VERSION "HIPBNYYYYYYYYYYYYYYYYYYYYYYYYYYYYYYYYYYYYY/4/%%%/4/'%**4YYY///"

NS_ :

BS_:

BU_: RMS_PM_Controller

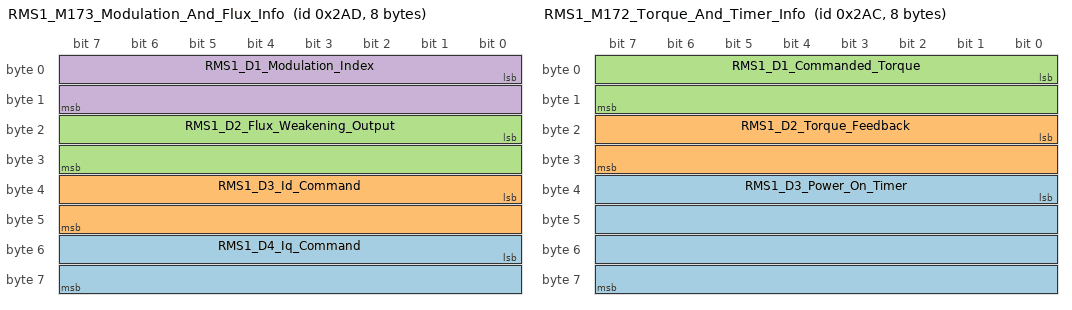
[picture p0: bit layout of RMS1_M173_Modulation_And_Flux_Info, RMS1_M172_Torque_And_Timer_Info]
BO_ 685 RMS1_M173_Modulation_And_Flux_Info: 8 RMS_PM_Controller
 SG_ RMS1_D4_Iq_Command : 48|16@1- (0.1,0) [-3276.8|3276.7] "A" Vector__XXX
 SG_ RMS1_D3_Id_Command : 32|16@1- (0.1,0) [-3276.8|3276.7] "A" Vector__XXX
 SG_ RMS1_D2_Flux_Weakening_Output : 16|16@1- (0.1,0) [-3276.8|3276.7] "A" Vector__XXX
 SG_ RMS1_D1_Modulation_Index : 0|16@1- (0.0001,0) [-3.2768|3.2767] "" Vector__XXX

BO_ 684 RMS1_M172_Torque_And_Timer_Info: 8 RMS_PM_Controller
 SG_ RMS1_D3_Power_On_Timer : 32|32@1+ (0.003,0) [0|1.28848e+007] "Sec" Vector__XXX
 SG_ RMS1_D2_Torque_Feedback : 16|16@1- (0.1,0) [-3276.8|3276.7] "Nm" Vector__XXX
 SG_ RMS1_D1_Commanded_Torque : 0|16@1- (0.1,0) [-3276.8|3276.7] "Nm" Vector__XXX

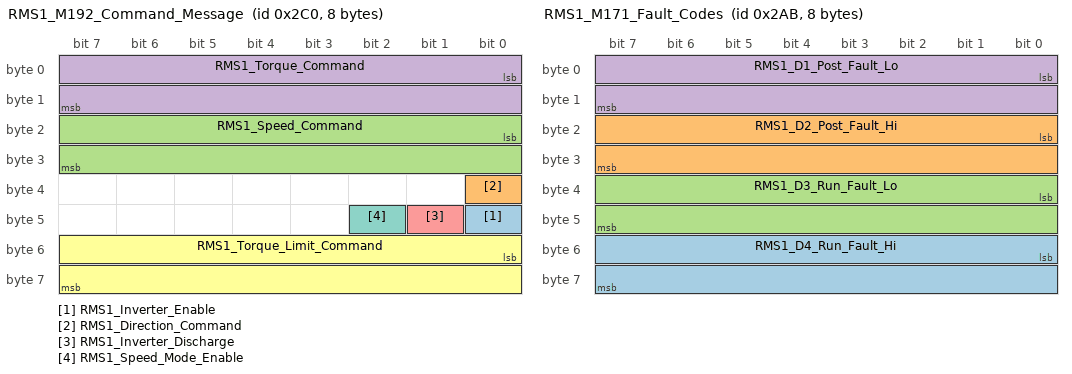
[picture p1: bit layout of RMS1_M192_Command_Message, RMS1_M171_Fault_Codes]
BO_ 704 RMS1_M192_Command_Message: 8 Vector__XXX
 SG_ RMS1_Inverter_Enable : 40|1@1+ (1,0) [0|1] "Bit" Vector__XXX
 SG_ RMS1_Direction_Command : 32|1@1+ (1,0) [0|1] "Bit" Vector__XXX
 SG_ RMS1_Speed_Command : 16|16@1- (1,0) [-32768|32767] "rpm" Vector__XXX
 SG_ RMS1_Torque_Command : 0|16@1- (0.1,0) [-3276.8|3276.7] "Nm" Vector__XXX
 SG_ RMS1_Inverter_Discharge : 41|1@1+ (1,0) [0|1] "Bit" Vector__XXX
 SG_ RMS1_Torque_Limit_Command : 48|16@1- (0.1,0) [-3276.8|3276.7] "Nm" Vector__XXX
 SG_ RMS1_Speed_Mode_Enable : 42|1@1+ (1,0) [0|1] "Bit" Vector__XXX

BO_ 683 RMS1_M171_Fault_Codes: 8 RMS_PM_Controller
 SG_ RMS1_D4_Run_Fault_Hi : 48|16@1+ (1,0) [0|65535] "" Vector__XXX
 SG_ RMS1_D2_Post_Fault_Hi : 16|16@1+ (1,0) [0|65535] "" Vector__XXX
 SG_ RMS1_D3_Run_Fault_Lo : 32|16@1+ (1,0) [0|65535] "" Vector__XXX
 SG_ RMS1_D1_Post_Fault_Lo : 0|16@1+ (1,0) [0|65535] "" Vector__XXX

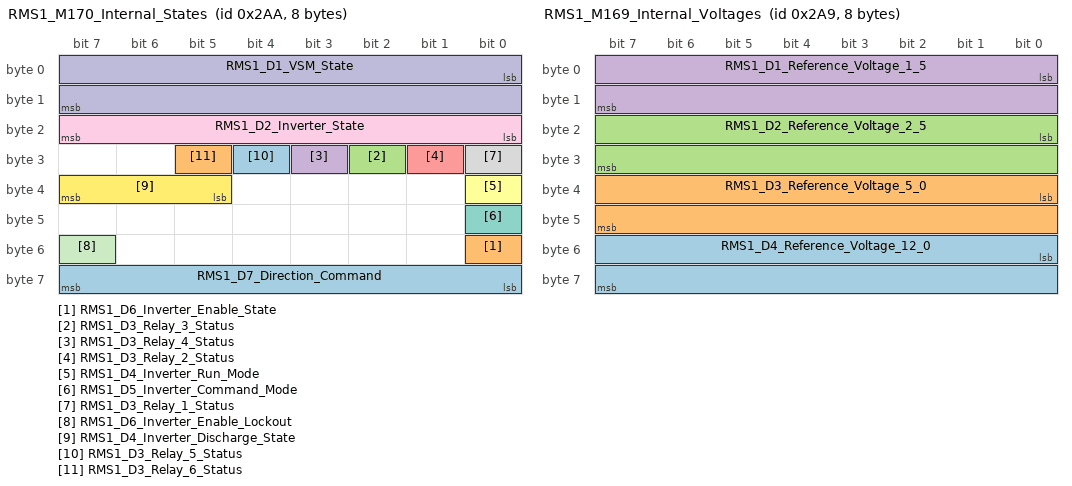
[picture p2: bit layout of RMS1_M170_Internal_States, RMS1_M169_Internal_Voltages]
BO_ 682 RMS1_M170_Internal_States: 8 RMS_PM_Controller
 SG_ RMS1_D7_Direction_Command : 56|8@1+ (1,0) [0|1] "" Vector__XXX
 SG_ RMS1_D6_Inverter_Enable_State : 48|1@1+ (1,0) [0|1] "" Vector__XXX
 SG_ RMS1_D3_Relay_3_Status : 26|1@1+ (1,0) [0|1] "" Vector__XXX
 SG_ RMS1_D3_Relay_4_Status : 27|1@1+ (1,0) [0|1] "" Vector__XXX
 SG_ RMS1_D3_Relay_2_Status : 25|1@1+ (1,0) [0|1] "" Vector__XXX
 SG_ RMS1_D4_Inverter_Run_Mode : 32|1@1+ (1,0) [0|1] "" Vector__XXX
 SG_ RMS1_D5_Inverter_Command_Mode : 40|1@1+ (1,0) [0|1] "" Vector__XXX
 SG_ RMS1_D3_Relay_1_Status : 24|1@1+ (1,0) [0|1] "" Vector__XXX
 SG_ RMS1_D2_Inverter_State : 16|8@1+ (1,0) [0|255] "" Vector__XXX
 SG_ RMS1_D1_VSM_State : 0|16@1+ (1,0) [0|15] "" Vector__XXX
 SG_ RMS1_D6_Inverter_Enable_Lockout : 55|1@1+ (1,0) [0|1] "" Vector__XXX
 SG_ RMS1_D4_Inverter_Discharge_State : 37|3@1+ (1,0) [0|7] "" Vector__XXX
 SG_ RMS1_D3_Relay_5_Status : 28|1@1+ (1,0) [0|1] "" Vector__XXX
 SG_ RMS1_D3_Relay_6_Status : 29|1@1+ (1,0) [0|1] "" Vector__XXX

BO_ 681 RMS1_M169_Internal_Voltages: 8 RMS_PM_Controller
 SG_ RMS1_D4_Reference_Voltage_12_0 : 48|16@1- (0.01,0) [-327.68|327.67] "V" Vector__XXX
 SG_ RMS1_D3_Reference_Voltage_5_0 : 32|16@1- (0.01,0) [-327.68|327.67] "V" Vector__XXX
 SG_ RMS1_D2_Reference_Voltage_2_5 : 16|16@1- (0.01,0) [-327.68|327.67] "V" Vector__XXX
 SG_ RMS1_D1_Reference_Voltage_1_5 : 0|16@1- (0.01,0) [-327.68|327.67] "V" Vector__XXX

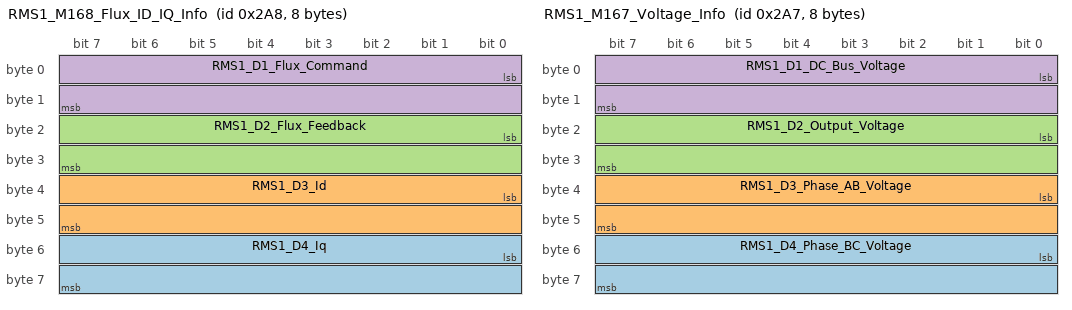
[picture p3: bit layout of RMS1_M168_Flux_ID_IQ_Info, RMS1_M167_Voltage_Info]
BO_ 680 RMS1_M168_Flux_ID_IQ_Info: 8 RMS_PM_Controller
 SG_ RMS1_D4_Iq : 48|16@1- (0.1,0) [-3276.8|3276.7] "A" Vector__XXX
 SG_ RMS1_D3_Id : 32|16@1- (0.1,0) [-3276.8|3276.7] "A" Vector__XXX
 SG_ RMS1_D2_Flux_Feedback : 16|16@1- (0.001,0) [-32.768|32.767] "Wb" Vector__XXX
 SG_ RMS1_D1_Flux_Command : 0|16@1- (0.001,0) [-32.768|32.767] "Wb" Vector__XXX

BO_ 679 RMS1_M167_Voltage_Info: 8 RMS_PM_Controller
 SG_ RMS1_D4_Phase_BC_Voltage : 48|16@1- (0.1,0) [-3276.8|3276.7] "V" Vector__XXX
 SG_ RMS1_D3_Phase_AB_Voltage : 32|16@1- (0.1,0) [-3276.8|3276.7] "V" Vector__XXX
 SG_ RMS1_D2_Output_Voltage : 16|16@1- (0.1,0) [-3276.8|3276.7] "V" Vector__XXX
 SG_ RMS1_D1_DC_Bus_Voltage : 0|16@1- (0.1,0) [-3276.8|3276.7] "V" Vector__XXX

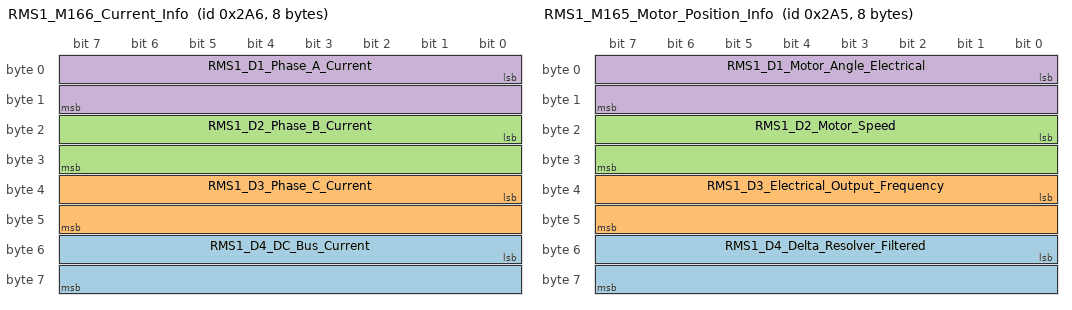
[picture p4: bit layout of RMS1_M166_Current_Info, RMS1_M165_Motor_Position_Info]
BO_ 678 RMS1_M166_Current_Info: 8 RMS_PM_Controller
 SG_ RMS1_D4_DC_Bus_Current : 48|16@1- (0.1,0) [-3276.8|3276.7] "A" Vector__XXX
 SG_ RMS1_D3_Phase_C_Current : 32|16@1- (0.1,0) [-3276.8|3276.7] "A" Vector__XXX
 SG_ RMS1_D2_Phase_B_Current : 16|16@1- (0.1,0) [-3276.8|3276.7] "A" Vector__XXX
 SG_ RMS1_D1_Phase_A_Current : 0|16@1- (0.1,0) [-3276.8|3276.7] "A" Vector__XXX

BO_ 677 RMS1_M165_Motor_Position_Info: 8 RMS_PM_Controller
 SG_ RMS1_D4_Delta_Resolver_Filtered : 48|16@1- (0.1,0) [-3276.8|3276.7] "deg" Vector__XXX
 SG_ RMS1_D3_Electrical_Output_Frequency : 32|16@1- (0.1,0) [-3276.8|3276.7] "hz" Vector__XXX
 SG_ RMS1_D2_Motor_Speed : 16|16@1- (1,0) [-32768|32767] "rpm" Vector__XXX
 SG_ RMS1_D1_Motor_Angle_Electrical : 0|16@1+ (0.1,0) [0|6553.5] "deg" Vector__XXX

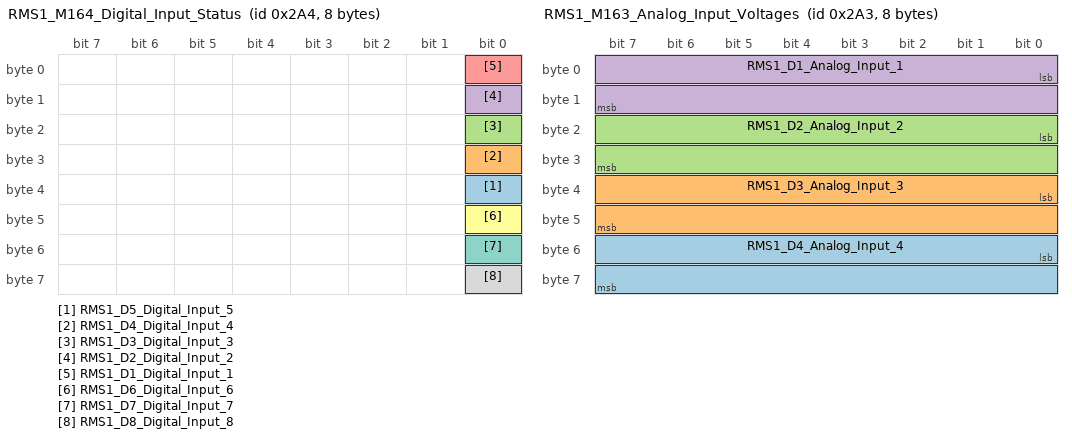
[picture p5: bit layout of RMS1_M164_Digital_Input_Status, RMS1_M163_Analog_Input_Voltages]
BO_ 676 RMS1_M164_Digital_Input_Status: 8 RMS_PM_Controller
 SG_ RMS1_D5_Digital_Input_5 : 32|1@1+ (1,0) [0|1] "boolean" Vector__XXX
 SG_ RMS1_D4_Digital_Input_4 : 24|1@1+ (1,0) [0|1] "boolean" Vector__XXX
 SG_ RMS1_D3_Digital_Input_3 : 16|1@1+ (1,0) [0|1] "boolean" Vector__XXX
 SG_ RMS1_D2_Digital_Input_2 : 8|1@1+ (1,0) [0|1] "boolean" Vector__XXX
 SG_ RMS1_D1_Digital_Input_1 : 0|1@1+ (1,0) [0|1] "boolean" Vector__XXX
 SG_ RMS1_D6_Digital_Input_6 : 40|1@1+ (1,0) [0|1] "boolean" Vector__XXX
 SG_ RMS1_D7_Digital_Input_7 : 48|1@1+ (1,0) [0|1] "boolean" Vector__XXX
 SG_ RMS1_D8_Digital_Input_8 : 56|1@1+ (1,0) [0|1] "boolean" Vector__XXX

BO_ 675 RMS1_M163_Analog_Input_Voltages: 8 RMS_PM_Controller
 SG_ RMS1_D4_Analog_Input_4 : 48|16@1- (0.01,0) [-327.68|327.67] "V" Vector__XXX
 SG_ RMS1_D3_Analog_Input_3 : 32|16@1- (0.01,0) [-327.68|327.67] "V" Vector__XXX
 SG_ RMS1_D2_Analog_Input_2 : 16|16@1- (0.01,0) [-327.68|327.67] "V" Vector__XXX
 SG_ RMS1_D1_Analog_Input_1 : 0|16@1- (0.01,0) [-327.68|327.67] "V" Vector__XXX

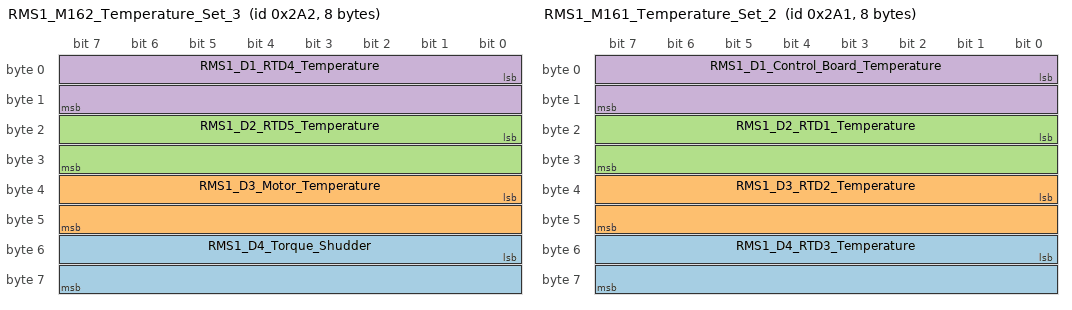
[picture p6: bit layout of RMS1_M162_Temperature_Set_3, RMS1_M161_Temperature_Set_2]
BO_ 674 RMS1_M162_Temperature_Set_3: 8 RMS_PM_Controller
 SG_ RMS1_D4_Torque_Shudder : 48|16@1- (0.1,0) [-3276.8|3276.7] "Nm" Vector__XXX
 SG_ RMS1_D3_Motor_Temperature : 32|16@1- (0.1,0) [-3276.8|3276.7] "degC" Vector__XXX
 SG_ RMS1_D2_RTD5_Temperature : 16|16@1- (0.1,0) [-3276.8|3276.7] "degC" Vector__XXX
 SG_ RMS1_D1_RTD4_Temperature : 0|16@1- (0.1,0) [-3276.8|3276.7] "degC" Vector__XXX

BO_ 673 RMS1_M161_Temperature_Set_2: 8 RMS_PM_Controller
 SG_ RMS1_D4_RTD3_Temperature : 48|16@1- (0.1,0) [-3276.8|3276.7] "degC" Vector__XXX
 SG_ RMS1_D3_RTD2_Temperature : 32|16@1- (0.1,0) [-3276.8|3276.7] "degC" Vector__XXX
 SG_ RMS1_D2_RTD1_Temperature : 16|16@1- (0.1,0) [-3276.8|3276.7] "degC" Vector__XXX
 SG_ RMS1_D1_Control_Board_Temperature : 0|16@1- (0.1,0) [-3276.8|3276.7] "degC" Vector__XXX

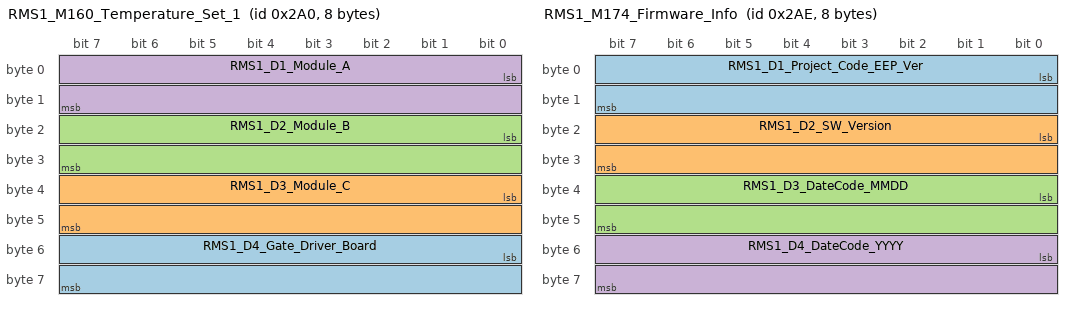
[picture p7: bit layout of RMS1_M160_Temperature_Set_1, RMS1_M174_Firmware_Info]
BO_ 672 RMS1_M160_Temperature_Set_1: 8 RMS_PM_Controller
 SG_ RMS1_D4_Gate_Driver_Board : 48|16@1- (0.1,0) [-3276.8|3276.7] "degC" Vector__XXX
 SG_ RMS1_D3_Module_C : 32|16@1- (0.1,0) [-3276.8|3276.7] "degC" Vector__XXX
 SG_ RMS1_D2_Module_B : 16|16@1- (0.1,0) [-3276.8|3276.7] "degC" Vector__XXX
 SG_ RMS1_D1_Module_A : 0|16@1- (0.1,0) [-3276.8|3276.7] "degC" Vector__XXX

BO_ 686 RMS1_M174_Firmware_Info: 8 RMS_PM_Controller
 SG_ RMS1_D1_Project_Code_EEP_Ver : 0|16@1+ (1,0) [0|65535] "" Vector__XXX
 SG_ RMS1_D2_SW_Version : 16|16@1+ (1,0) [0|65535] "" Vector__XXX
 SG_ RMS1_D3_DateCode_MMDD : 32|16@1+ (1,0) [0|65535] "" Vector__XXX
 SG_ RMS1_D4_DateCode_YYYY : 48|16@1+ (1,0) [0|65535] "" Vector__XXX

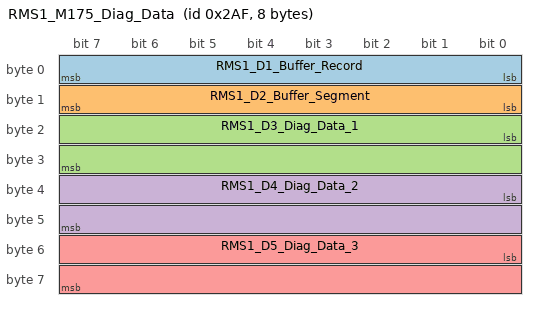
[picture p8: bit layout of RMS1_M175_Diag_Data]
BO_ 687 RMS1_M175_Diag_Data: 8 RMS_PM_Controller
 SG_ RMS1_D1_Buffer_Record : 0|8@1+ (1,0) [0|255] "" Vector__XXX
 SG_ RMS1_D2_Buffer_Segment : 8|8@1+ (1,0) [0|5] "" Vector__XXX
 SG_ RMS1_D3_Diag_Data_1 : 16|16@1- (1,0) [-32768|32767] "" Vector__XXX
 SG_ RMS1_D4_Diag_Data_2 : 32|16@1- (1,0) [-32768|32767] "" Vector__XXX
 SG_ RMS1_D5_Diag_Data_3 : 48|16@1- (1,0) [-32768|32767] "" Vector__XXX

CM_ SG_ 685 RMS1_D4_Iq_Command "The commanded Q-axis current";
CM_ SG_ 685 RMS1_D3_Id_Command "The commanded D-axis current";
CM_ SG_ 685 RMS1_D2_Flux_Weakening_Output "This is the current output of the flux regulator.";
CM_ SG_ 685 RMS1_D1_Modulation_Index "This is the modulation index. The scale factor is x100. To get the actual modulation index divide the value by 100.";
CM_ SG_ 684 RMS1_D3_Power_On_Timer "Updated every 3 msec. This will roll over in approximately 150 days!";
CM_ SG_ 684 RMS1_D2_Torque_Feedback "Estimated motor torque feedback";
CM_ SG_ 684 RMS1_D1_Commanded_Torque "The commanded Torque";
CM_ BO_ 704 "The command message is used to transmit data to the controller. This message is sent from a user supplied external controller to the PMxxx controller.";
CM_ SG_ 704 RMS1_Inverter_Enable "0=Inverter OFF, 1 = Inverter ON";
CM_ SG_ 704 RMS1_Direction_Command "0=CW, 1=CCW as veiwed from the shaft end of the motor";
CM_ SG_ 704 RMS1_Speed_Command "Speed commandused when in speed mode";
CM_ SG_ 704 RMS1_Torque_Command "Torque command when in torque mode";
CM_ SG_ 704 RMS1_Inverter_Discharge "0=Discharge Disable,
=Discharge Enable";
CM_ SG_ 704 RMS1_Torque_Limit_Command "Torque Limit, set to 0 to keep default";
CM_ SG_ 704 RMS1_Speed_Mode_Enable "0 = No change to mode, 1 = change to speed mode from torque mode";
CM_ SG_ 683 RMS1_D4_Run_Fault_Hi "Each bit represents a fault. Please refer to PM100 Users Manual for details.";
CM_ SG_ 683 RMS1_D2_Post_Fault_Hi "Each bit represents a fault. Please refer to PM100 Users Manual for details.";
CM_ SG_ 683 RMS1_D3_Run_Fault_Lo "Each bit represents a fault. Please refer to PM100 Users Manual for details.";
CM_ SG_ 683 RMS1_D1_Post_Fault_Lo "Each bit represents a fault. Please refer to PM100 Users Manual for details.";
CM_ SG_ 682 RMS1_D7_Direction_Command "1 = Forward
0 = 'Reverse' if inverter enabled  & 'Stopped' if inverter is disabled";
CM_ SG_ 682 RMS1_D6_Inverter_Enable_State "0=Inverter Disabled, 
1=Inverter Enabled";
CM_ SG_ 682 RMS1_D3_Relay_3_Status "0=OFF, 1=ON";
CM_ SG_ 682 RMS1_D3_Relay_4_Status "0=OFF, 1=ON";
CM_ SG_ 682 RMS1_D3_Relay_2_Status "0=OFF, 1=ON";
CM_ SG_ 682 RMS1_D4_Inverter_Run_Mode "0=Torque Mode, 1=Speed Mode";
CM_ SG_ 682 RMS1_D5_Inverter_Command_Mode "0=CAN mode, 1=VSM mode";
CM_ SG_ 682 RMS1_D3_Relay_1_Status "0=OFF, 1=ON";
CM_ SG_ 682 RMS1_D2_Inverter_State "Different states for the inverter state machine";
CM_ SG_ 682 RMS1_D1_VSM_State "Different states for the vehicle state machine";
CM_ SG_ 682 RMS1_D6_Inverter_Enable_Lockout "0=Lockout Disabled, 1=Lockout Enabled";
CM_ SG_ 682 RMS1_D4_Inverter_Discharge_State "0 = Disabled, 1 = Enabled, 2 = Speed Check, 3 = Active, 4 = Complete";
CM_ SG_ 682 RMS1_D3_Relay_5_Status "0=OFF, 1=ON";
CM_ SG_ 682 RMS1_D3_Relay_6_Status "0=OFF, 1=ON";
CM_ SG_ 681 RMS1_D4_Reference_Voltage_12_0 "12V Input Voltage";
CM_ SG_ 681 RMS1_D3_Reference_Voltage_5_0 "Transducer voltage";
CM_ SG_ 681 RMS1_D2_Reference_Voltage_2_5 "Internal reference voltage";
CM_ SG_ 681 RMS1_D1_Reference_Voltage_1_5 "Internal reference voltage";
CM_ SG_ 680 RMS1_D4_Iq "The measured Iq current";
CM_ SG_ 680 RMS1_D3_Id "The measured Id current";
CM_ SG_ 680 RMS1_D2_Flux_Feedback "The estimated flux";
CM_ SG_ 680 RMS1_D1_Flux_Command "The commanded flux";
CM_ SG_ 679 RMS1_D4_Phase_BC_Voltage "Measured value of the voltage between Phase B and Phase C";
CM_ SG_ 679 RMS1_D3_Phase_AB_Voltage "Measured value of the voltage betwen phase A and Phase B";
CM_ SG_ 679 RMS1_D2_Output_Voltage "The calculated value of the output voltage, in peak line-neutral volts";
CM_ SG_ 679 RMS1_D1_DC_Bus_Voltage "The actual measured value of the DC bus voltage";
CM_ SG_ 678 RMS1_D4_DC_Bus_Current "The Calculated DC Bus Current";
CM_ SG_ 678 RMS1_D3_Phase_C_Current "The measured value of Phase C current";
CM_ SG_ 678 RMS1_D2_Phase_B_Current "The measured value of Phase B current";
CM_ SG_ 678 RMS1_D1_Phase_A_Current "The measured value of Phase A current";
CM_ SG_ 677 RMS1_D4_Delta_Resolver_Filtered "Used in calibration of resolver angle adjustment.";
CM_ SG_ 677 RMS1_D3_Electrical_Output_Frequency "The actual electrical frequency of the inverter";
CM_ SG_ 677 RMS1_D2_Motor_Speed "The measured speed of the motor";
CM_ SG_ 677 RMS1_D1_Motor_Angle_Electrical "The Electrical Angle of the motor as read by the encoder or resolver";
CM_ SG_ 676 RMS1_D5_Digital_Input_5 "Status of Digital Input #5";
CM_ SG_ 676 RMS1_D4_Digital_Input_4 "Status of Digital Input #4";
CM_ SG_ 676 RMS1_D3_Digital_Input_3 "Status of Digital Input #3";
CM_ SG_ 676 RMS1_D2_Digital_Input_2 "Status of Digital Input #2";
CM_ SG_ 676 RMS1_D1_Digital_Input_1 "Status of Digital Input #1";
CM_ SG_ 676 RMS1_D6_Digital_Input_6 "Status of Digital Input #6";
CM_ SG_ 676 RMS1_D7_Digital_Input_7 "Status of Digital Input #7";
CM_ SG_ 676 RMS1_D8_Digital_Input_8 "Status of Digital Input #8";
CM_ SG_ 675 RMS1_D4_Analog_Input_4 "Voltage on Analog Input #4";
CM_ SG_ 675 RMS1_D3_Analog_Input_3 "Voltage on Analog Input #3";
CM_ SG_ 675 RMS1_D2_Analog_Input_2 "Voltage on Analog Input #2";
CM_ SG_ 675 RMS1_D1_Analog_Input_1 "Voltage on Analog Input #1";
CM_ SG_ 674 RMS1_D4_Torque_Shudder "Shudder compensation value of torque";
CM_ SG_ 674 RMS1_D3_Motor_Temperature "Motor Temperature Sensor";
CM_ SG_ 674 RMS1_D2_RTD5_Temperature "RTD 5 (PT1000) Temperature";
CM_ SG_ 674 RMS1_D1_RTD4_Temperature "RTD 4 (PT1000) Temperature";
CM_ SG_ 673 RMS1_D4_RTD3_Temperature "RTD input 3 (PT1000) Temperature";
CM_ SG_ 673 RMS1_D3_RTD2_Temperature "RTD input 2 (PT1000) Temperature";
CM_ SG_ 673 RMS1_D2_RTD1_Temperature "RTD input 1 (PT1000) Temperature";
CM_ SG_ 673 RMS1_D1_Control_Board_Temperature "Control Board Temperature";
CM_ SG_ 672 RMS1_D4_Gate_Driver_Board "Gate Driver Board Temperature";
CM_ SG_ 672 RMS1_D3_Module_C "IGBT Module C Temperature";
CM_ SG_ 672 RMS1_D2_Module_B "IGBT Module B Temperature";
CM_ SG_ 672 RMS1_D1_Module_A "IGBT Module A Temperature";
BA_DEF_ BO_  "GenMsgCycleTime" INT 0 100000;
BA_DEF_  "BusType" STRING ;
BA_DEF_DEF_  "GenMsgCycleTime" 0;
BA_DEF_DEF_  "BusType" "CAN";
BA_ "GenMsgCycleTime" BO_ 684 10;
BA_ "GenMsgCycleTime" BO_ 704 5;
BA_ "GenMsgCycleTime" BO_ 683 100;
BA_ "GenMsgCycleTime" BO_ 682 100;
BA_ "GenMsgCycleTime" BO_ 681 100;
BA_ "GenMsgCycleTime" BO_ 680 10;
BA_ "GenMsgCycleTime" BO_ 679 10;
BA_ "GenMsgCycleTime" BO_ 678 10;
BA_ "GenMsgCycleTime" BO_ 677 10;
BA_ "GenMsgCycleTime" BO_ 676 10;
BA_ "GenMsgCycleTime" BO_ 675 10;
BA_ "GenMsgCycleTime" BO_ 674 100;
BA_ "GenMsgCycleTime" BO_ 673 100;
BA_ "GenMsgCycleTime" BO_ 672 100;
